# ATSAMR34J17B device description
Architecture: CORTEX-M0PLUS; Family: SAMR; Series: SAMR34
Registers are 32-bit, read-write, reset 0x0 unless marked. A register's access mark holds for its fields unless they carry their own. Offsets are from the block's base; [hi:lo] are bit positions; 'fields as' and 'values as' point back to an identical list.

## OTP5_FUSES — Non-Volatile Fuses
Instances: OTP5_FUSES 0x00806020 in fuses
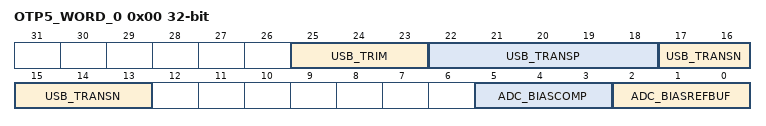
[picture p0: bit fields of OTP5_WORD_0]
0x00 OTP5_WORD_0 ro reset not defined — OTP5 Page Word 0
  [25:23] USB_TRIM — USB pad Trim calibration
  [22:18] USB_TRANSP — USB pad Transp calibration
  [17:13] USB_TRANSN — USB pad Transn calibration
  [5:3] ADC_BIASCOMP — ADC Comparator Scaling
  [2:0] ADC_BIASREFBUF — ADC Bias Reference Buffer Scaling

## TEMP_LOG_FUSES — Non-Volatile Fuses
Instances: TEMP_LOG_FUSES 0x00806030 in fuses
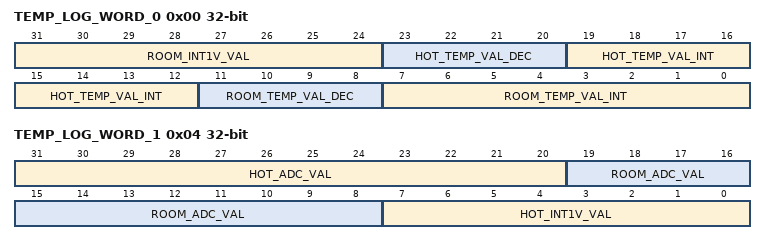
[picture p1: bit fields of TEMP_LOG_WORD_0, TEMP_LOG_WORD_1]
0x00 TEMP_LOG_WORD_0 ro reset not defined — TEMP_LOG Page Word 0
  [31:24] ROOM_INT1V_VAL — 2's complement of the internal 1V reference drift at room temperature (versus a 1.0 centered value)
  [23:20] HOT_TEMP_VAL_DEC — Decimal part of hot temperature
  [19:12] HOT_TEMP_VAL_INT — Integer part of hot temperature in oC
  [11:8] ROOM_TEMP_VAL_DEC — Decimal part of room temperature
  [7:0] ROOM_TEMP_VAL_INT — Integer part of room temperature in oC
0x04 TEMP_LOG_WORD_1 ro reset not defined — TEMP_LOG Page Word 1
  [31:20] HOT_ADC_VAL — 12-bit ADC conversion at hot temperature
  [19:8] ROOM_ADC_VAL — 12-bit ADC conversion at room temperature
  [7:0] HOT_INT1V_VAL — 2's complement of the internal 1V reference drift at hot temperature (versus a 1.0 centered value)

## USER_FUSES — Non-Volatile Fuses
Instances: USER_FUSES 0x00804000 in fuses
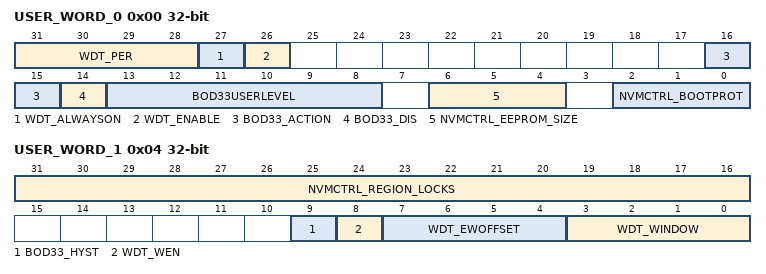
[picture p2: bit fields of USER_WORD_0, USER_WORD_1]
0x00 USER_WORD_0 reset not defined — USER Page Word 0
  [31:28] WDT_PER — WDT Period
    0=CYC8 (8 clock cycles); 1=CYC16 (16 clock cycles); 2=CYC32 (32 clock cycles); 3=CYC64 (64 clock cycles); 4=CYC128 (128 clock cycles); 5=CYC256 (256 clock cycles); 6=CYC512 (512 clock cycles); 7=CYC1024 (1024 clock cycles); 8=CYC2048 (2048 clock cycles); 9=CYC4096 (4096 clock cycles); 10=CYC8192 (8192 clock cycles); 11=CYC16384 (16384 clock cycles)
  [27] WDT_ALWAYSON
  [26] WDT_ENABLE
  [16:15] BOD33_ACTION
    0=NONE (No action); 1=RESET (The BOD33 generates a reset); 2=INT (The BOD33 generates an interrupt); 3=BKUP (The BOD33 puts the device in backup sleep mode)
  [14] BOD33_DIS — BOD33 Disable
  [13:8] BOD33USERLEVEL
  [6:4] NVMCTRL_EEPROM_SIZE — EEPROM Size
    7=SIZE_0BYTES (0 Bytes); 6=SIZE_256BYTES (256 Bytes); 5=SIZE_512BYTES (512 Bytes); 4=SIZE_1024BYTES (1024 Bytes); 3=SIZE_2048BYTES (2048 Bytes); 2=SIZE_4096BYTES (4096 Bytes); 1=SIZE_8192BYTES (8192 Bytes); 0=SIZE_16384BYTES (16384 Bytes)
  [2:0] NVMCTRL_BOOTPROT — Bootloader Size
    7=SIZE_0BYTES (0 Bytes); 6=SIZE_512BYTES (512 Bytes); 5=SIZE_1024BYTES (1024 Bytes); 4=SIZE_2048BYTES (2048 Bytes); 3=SIZE_4096BYTES (4096 Bytes); 2=SIZE_8192BYTES (8192 Bytes); 1=SIZE_16384BYTES (16384 Bytes); 0=SIZE_32768BYTES (32768 Bytes)
0x04 USER_WORD_1 reset not defined — USER Page Word 1
  [31:16] NVMCTRL_REGION_LOCKS — NVM Region Locks
  [9] BOD33_HYST — BOD33 Hysteresis
  [8] WDT_WEN — WDT Window Mode Enable
  [7:4] WDT_EWOFFSET — WDT Early Warning Offset
    values as USER_WORD_0.WDT_PER
  [3:0] WDT_WINDOW
    values as USER_WORD_0.WDT_PER

## OSC32KCTRL — 32k Oscillators Control
Instances: OSC32KCTRL 0x40001000
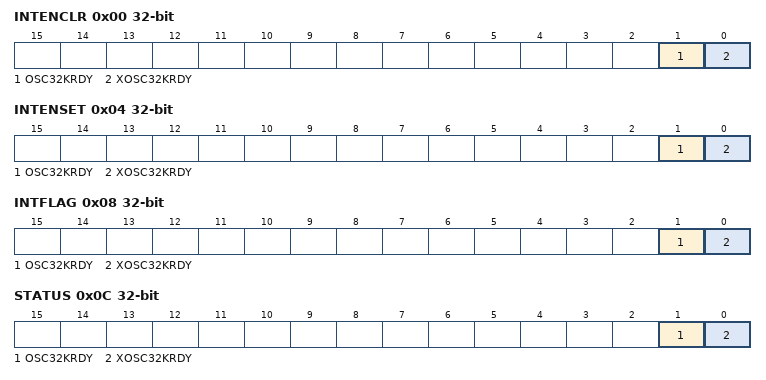
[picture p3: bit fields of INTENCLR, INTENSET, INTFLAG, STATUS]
0x00 INTENCLR (atomic clear) — Interrupt Enable Clear
  [1] OSC32KRDY — OSC32K Ready Interrupt Enable
  [0] XOSC32KRDY — XOSC32K Ready Interrupt Enable
0x04 INTENSET (atomic set) — Interrupt Enable Set
  fields as INTENCLR
0x08 INTFLAG (atomic clear) — Interrupt Flag Status and Clear
  [1] OSC32KRDY — OSC32K Ready
  [0] XOSC32KRDY — XOSC32K Ready
0x0C STATUS ro — Power and Clocks Status
  [1] OSC32KRDY — OSC32K Ready
  [0] XOSC32KRDY — XOSC32K Ready
0x10 RTCCTRL — Clock selection
  [2:0] RTCSEL — RTC Clock Selection
    0=ULP1K (1.024kHz from 32kHz internal ULP oscillator); 1=ULP32K (32.768kHz from 32kHz internal ULP oscillator); 2=OSC1K (1.024kHz from 32.768kHz internal oscillator); 3=OSC32K (32.768kHz from 32.768kHz internal oscillator); 4=XOSC1K (1.024kHz from 32.768kHz internal oscillator); 5=XOSC32K (32.768kHz from 32.768kHz external crystal oscillator)
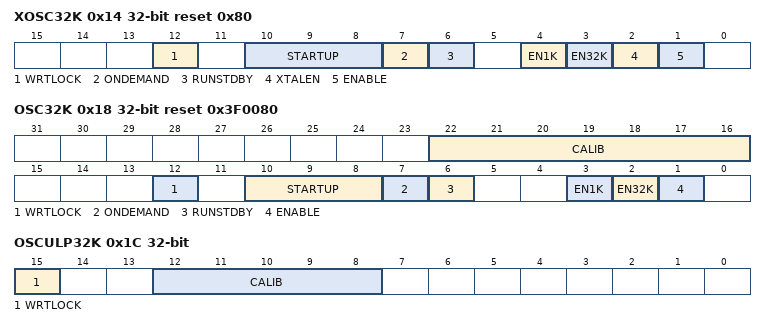
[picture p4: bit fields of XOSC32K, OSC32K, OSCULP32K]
0x14 XOSC32K reset 0x80 — 32kHz External Crystal Oscillator (XOSC32K) Control
  [12] WRTLOCK — Write Lock
  [10:8] STARTUP — Oscillator Start-Up Time
    0=CYCLE2048 (62.5 ms); 1=CYCLE4096 (125 ms); 2=CYCLE16384 (500 ms); 3=CYCLE32768 (1000 ms); 4=CYCLE65536 (2000 ms); 5=CYCLE131072 (4000 ms); 6=CYCLE262144 (8000 ms)
  [7] ONDEMAND — On Demand Control
  [6] RUNSTDBY — Run in Standby
  [4] EN1K — 1kHz Output Enable
  [3] EN32K — 32kHz Output Enable
  [2] XTALEN — Crystal Oscillator Enable
  [1] ENABLE — Oscillator Enable
0x18 OSC32K reset 0x3F0080 — 32kHz Internal Oscillator (OSC32K) Control
  [22:16] CALIB — Oscillator Calibration
  [12] WRTLOCK — Write Lock
  [10:8] STARTUP — Oscillator Start-Up Time
    0=CYCLE3 (0.092 ms); 1=CYCLE4 (0.122 ms); 2=CYCLE6 (0.183 ms); 3=CYCLE10 (0.305 ms); 4=CYCLE18 (0.549 ms); 5=CYCLE34 (1.038 ms); 6=CYCLE66 (2.014 ms); 7=CYCLE130 (3.967 ms)
  [7] ONDEMAND — On Demand Control
  [6] RUNSTDBY — Run in Standby
  [3] EN1K — 1kHz Output Enable
  [2] EN32K — 32kHz Output Enable
  [1] ENABLE — Oscillator Enable
0x1C OSCULP32K reset not defined — 32kHz Ultra Low Power Internal Oscillator (OSCULP32K) Control
  [15] WRTLOCK — Write Lock
  [12:8] CALIB — Oscillator Calibration

## Notices in the file
Copyright (c) 2018 Microchip Technology Inc.
SPDX-License-Identifier: Apache-2.0
Licensed under the Apache License, Version 2.0 (the "License");
you may not use this file except in compliance with the License.
You may obtain a copy of the License at
http://www.apache.org/licenses/LICENSE-2.0
Unless required by applicable law or agreed to in writing, software
distributed under the License is distributed on an "AS IS" BASIS,
WITHOUT WARRANTIES OR CONDITIONS OF ANY KIND, either express or implied.
See the License for the specific language governing permissions and
limitations under the License.
